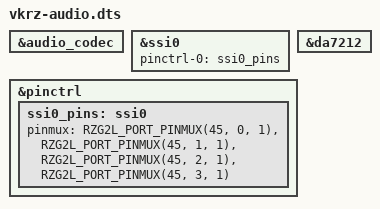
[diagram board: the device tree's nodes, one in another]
/*
 * Copyright 2023 Vekatech
 *
 * This program is free software; you can redistribute it and/or
 * modify it under the terms of the GNU General Public License
 * as published by the Free Software Foundation; either version 2
 * of the License, or (at your option) any later version.
 *
 * This program is distributed in the hope that it will be useful,
 * but WITHOUT ANY WARRANTY; without even the implied warranty of
 * MERCHANTABILITY or FITNESS FOR A PARTICULAR PURPOSE. See the
 * GNU General Public License for more details.
 */

#include <dt-bindings/interrupt-controller/arm-gic.h>
#include <dt-bindings/pinctrl/rzg2l-pinctrl.h>
#include <dt-bindings/gpio/gpio.h>

/dts-v1/;
/plugin/;


&audio_codec {
	status = "okay";
};

&ssi0 {
	pinctrl-0 = <&ssi0_pins>;
	pinctrl-names = "default";
	status = "okay";
};

&da7212 {
	status = "okay";
};

&pinctrl {
	ssi0_pins: ssi0 {
		pinmux = <RZG2L_PORT_PINMUX(45, 0, 1)>, /* BCK */
			 <RZG2L_PORT_PINMUX(45, 1, 1)>, /* RCK */
			 <RZG2L_PORT_PINMUX(45, 2, 1)>, /* TXD */
			 <RZG2L_PORT_PINMUX(45, 3, 1)>; /* RXD */
	};
};

